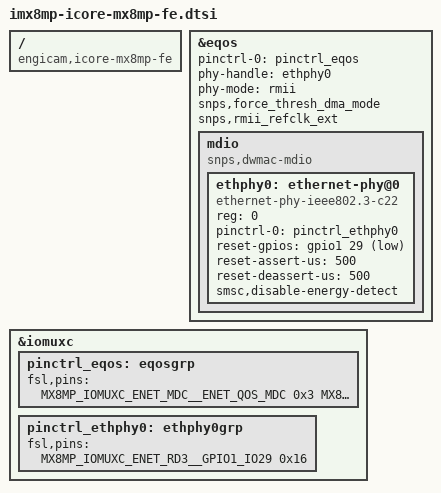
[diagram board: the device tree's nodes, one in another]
// SPDX-License-Identifier: (GPL-2.0+ OR MIT)
/*
 * Copyright (C) 2026 Amarula Solutions, Dario Binacchi <dario.binacchi@amarulasolutions.com>
 * Copyright (C) 2026 Engicam srl
 */

#include "imx8mp-icore-mx8mp.dtsi"

/ {
	compatible = "engicam,icore-mx8mp-fe", "fsl,imx8mp";
};

&eqos {
	pinctrl-names = "default";
	pinctrl-0 = <&pinctrl_eqos>;
	phy-handle = <&ethphy0>;
	phy-mode = "rmii";
	snps,force_thresh_dma_mode;
	snps,rmii_refclk_ext;
	status = "okay";

	mdio {
		compatible = "snps,dwmac-mdio";
		#address-cells = <1>;
		#size-cells = <0>;

		ethphy0: ethernet-phy@0 {	/* SMSC LAN8710 */
			compatible = "ethernet-phy-ieee802.3-c22";
			reg = <0>;
			pinctrl-names = "default";
			pinctrl-0 = <&pinctrl_ethphy0>;
			reset-gpios = <&gpio1 29 GPIO_ACTIVE_LOW>;
			reset-assert-us = <500>;
			reset-deassert-us = <500>;
			smsc,disable-energy-detect;
		};
	};
};

&iomuxc {
	pinctrl_eqos: eqosgrp {
		fsl,pins = <
			MX8MP_IOMUXC_ENET_MDC__ENET_QOS_MDC				0x3
			MX8MP_IOMUXC_ENET_MDIO__ENET_QOS_MDIO				0x3
			MX8MP_IOMUXC_ENET_TX_CTL__ENET_QOS_RGMII_TX_CTL			0x12
			MX8MP_IOMUXC_ENET_TD0__ENET_QOS_RGMII_TD0			0x12
			MX8MP_IOMUXC_ENET_TD1__ENET_QOS_RGMII_TD1			0x12
			/* RMII reference clock input, provided by the SoM */
			MX8MP_IOMUXC_ENET_TD2__CCM_ENET_QOS_CLOCK_GENERATE_REF_CLK	0x12
			MX8MP_IOMUXC_ENET_RX_CTL__ENET_QOS_RGMII_RX_CTL			0x1d0
			MX8MP_IOMUXC_ENET_RXC__ENET_QOS_RX_ER				0x91
			MX8MP_IOMUXC_ENET_RD0__ENET_QOS_RGMII_RD0			0x1d0
			MX8MP_IOMUXC_ENET_RD1__ENET_QOS_RGMII_RD1			0x1d0
		>;
	};

	pinctrl_ethphy0: ethphy0grp {
		fsl,pins = <
			MX8MP_IOMUXC_ENET_RD3__GPIO1_IO29	0x16
		>;
	};
};
